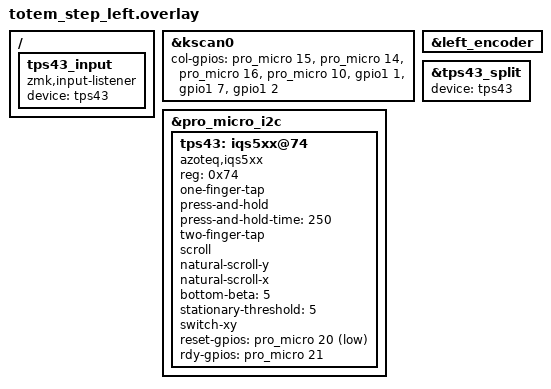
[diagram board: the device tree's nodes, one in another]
#include "totem_step.dtsi" // The shared dtsi file is included in the overlay

// Label of the kscan node in the dtsi
&kscan0 {
    col-gpios
        = <&pro_micro 15 GPIO_ACTIVE_HIGH>
        , <&pro_micro 14 GPIO_ACTIVE_HIGH>
        , <&pro_micro 16 GPIO_ACTIVE_HIGH>
        , <&pro_micro 10 GPIO_ACTIVE_HIGH>
        , <&gpio1 1 GPIO_ACTIVE_HIGH>
        , <&gpio1 7 GPIO_ACTIVE_HIGH>
        , <&gpio1 2 GPIO_ACTIVE_HIGH>
        ;
};

&left_encoder {
    status = "okay";
};

&pro_micro_i2c {
    status = "okay";

    tps43: iqs5xx@74 {
        status = "okay";
        compatible = "azoteq,iqs5xx";
        reg = <0x74>;

        /*
         * Potentially non-exhaustive list of configuration options.
         * See: dts/bindings/input/azoteq,iqs5xx-common.yaml for a full list.
         */
        one-finger-tap;
        press-and-hold;
        press-and-hold-time = <250>;
        two-finger-tap;

        scroll;
        natural-scroll-y;
        natural-scroll-x;

        bottom-beta = <5>;
        stationary-threshold = <5>;

        switch-xy;

        reset-gpios = <&pro_micro 20 GPIO_ACTIVE_LOW>;
        rdy-gpios = <&pro_micro 21 GPIO_ACTIVE_HIGH>;
    };
};

/ {
    tps43_input: tps43_input {
        compatible = "zmk,input-listener";
        device = <&tps43>;
    };
};

&tps43_split {
    device = <&tps43>;
};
